# LPC18xx register map
File version: 18
Registers are 32-bit, read-write, reset 0x0 unless marked. A register's access mark holds for its fields unless they carry their own. Offsets are from the block's base; [hi:lo] are bit positions; {n}, {i} and the like mark numbered series.

## DAC — Product name title=UM10430 Chapter title=LPC18xx DAC Modification date=1/18/2011 Major revision=0 Minor revision=7
Base 0x400E1000
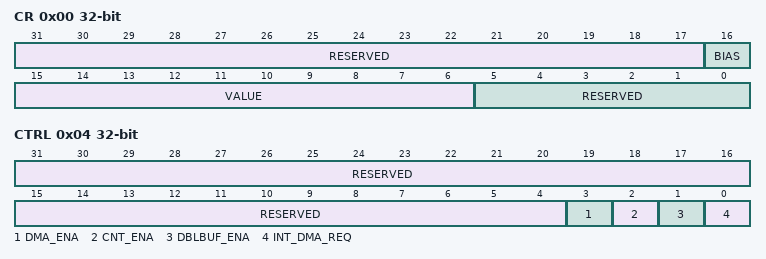
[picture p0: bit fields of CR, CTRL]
0x00 CR — DAC register. Holds the conversion data.
  [31:17] RESERVED — Reserved, user software should not write ones to reserved bits. The value read from a reserved bit is not defined.
  [16] BIAS — Settling time
    0=SHORT (The settling time of the DAC is 1 micros max, and the maximum current is 700 microA.); 1=LONG (The settling time of the DAC is 2.5 micros and the maximum current is 350 microA.)
  [15:6] VALUE — After the selected settling time after this field is written with a new VALUE, the voltage on the DACOUT pin (with respect to VSSA) is VALUE/1024 X VDDA.
  [5:0] RESERVED — Reserved, user software should not write ones to reserved bits. The value read from a reserved bit is not defined.
0x04 CTRL — DAC control register.
  [31:4] RESERVED — Reserved, user software should not write ones to reserved bits. The value read from a reserved bit is not defined.
  [3] DMA_ENA — DMA enable
    0=DISABLED (DMA access is disabled.); 1=ENABLED (DMA Burst Request Input 15 is enabled for the DAC (see Table 136).)
  [2] CNT_ENA — DMA time-out
    0=DISABLED (Time-out counter operation is disabled.); 1=ENABLED (Time-out counter operation is enabled.)
  [1] DBLBUF_ENA — DMA double-buffering
    0=DISABLED (DACR double-buffering is disabled.); 1=ENABLED (When this bit and the CNT_ENA bit are both set, the double-buffering feature in the DACR register will be enabled. Writes to the DACR register are written to a pre-buffer and then transferred to the DACR on the next time-out of the counter.)
  [0] INT_DMA_REQ — DMA request
    0=CLR (This bit is cleared on any write to the DACR register.); 1=SET (This bit is set by hardware when the timer times out.)
0x08 CNTVAL — DAC counter value register.
  [15:0] VALUE — 16-bit reload value for the DAC interrupt/DMA timer.

## GPIO_PORT
Base 0x400F4000
{0x0+i} B{i} (i=0..255) 8-bit — Byte pin registers port 0 to 5; pins PIOn_0 to PIOn_31
  [0] PBYTE — Read: state of the GPIOm[n] pin, regardless of direction, masking, or alternate function, except that pins configured as analog I/O always read as 0. Write: loads the pin's output bit.
{0x1000+4i} W{i} (i=0..255) — Word pin registers port 0 to 5
  [31:0] PWORD — Read 0: pin is LOW. Write 0: clear output bit. Read 0xFFFF FFFF: pin is HIGH. Write any value 0x0000 0001 to 0xFFFF FFFF: set output bit. Only 0 or 0xFFFF FFFF can be read. Writing any value other than 0 will set the output bit.
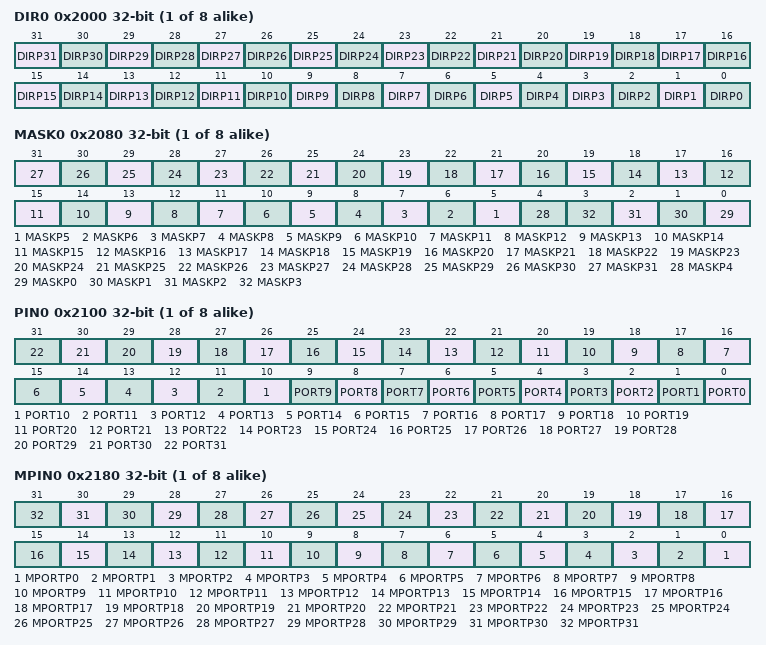
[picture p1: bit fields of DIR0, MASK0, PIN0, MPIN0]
{0x2000+4i} DIR{i} (i=0..7) — Direction registers port m
  [n] DIRP{n} (n=5..31) — Selects pin direction for pin GPIOm[n] (bit 0 = GPIOm[0], bit 1 = GPIOm[1], ..., bit 31 = GPIOm[31]). 0 = input. 1 = output.
  [n] DIRP{n} (n=0..4) — Selects pin direction for GPIOm[n] pin (bit 0 = GPIOm[0], bit 1 = GPIOm[1], ..., bit 31 = GPIOm[31]). 0 = input. 1 = output.
{0x2080+4i} MASK{i} (i=0..7) — Mask register port m
  [n] MASKP{n} (n=5..31) — Controls which bits corresponding to GPIOm[n] are active in the PIN register (bit 0 = GPIOm[0], bit 1 = GPIOm[1], ..., bit 31 = GPIOm[31]). 0 = Read MPORT: pin state; write MPORT: load output bit. 1 = Read MPORT: 0; write MPORT: output bit not affected.
  [4] MASKP4 — Controls which bits corresponding to GPIOm[n] are active in the P0/1PIN register (bit 0 = GPIOm[0], bit 1 = GPIOm[1], ..., bit 31 = GPIOm[31]). 0 = Read MPORT: pin state; write MPORT: load output bit. 1 = Read MPORT: 0; write MPORT: output bit not affected.
  [n] MASKP{n} (n=0..3) — Controls which bits corresponding to GPIOm[n] are active in the PIN register (bit 0 = GPIOm[0], bit 1 = GPIOm[1], ..., bit 31 = GPIOm[31]). 0 = Read MPORT: pin state; write MPORT: load output bit. 1 = Read MPORT: 0; write MPORT: output bit not affected.
{0x2100+4i} PIN{i} (i=0..7) — Port pin register port m
  [n] PORT{n} (n=0..31) — Reads pin states or loads output bits (bit 0 = GPIOm[0], bit 1 = GPIOm[1], ..., bit 31 = GPIOm[31]). 0 = Read: pin is low; write: clear output bit. 1 = Read: pin is high; write: set output bit.
{0x2180+4i} MPIN{i} (i=0..7) — Masked port register port m
  [n] MPORTP{n} (n=0..31) — Masked port register (bit 0 = GPIOm[0], bit 1 = GPIOm[1], ..., bit 31 = GPIOm[31]). 0 = Read: pin is LOW and/or the corresponding bit in the MASK register is 1; write: clear output bit if the corresponding bit in the MASK register is 0. 1 = Read: pin is HIGH and the corresponding bit in the MASK register is 0; write: set output bit if the corresponding bit in the MASK register is 0.
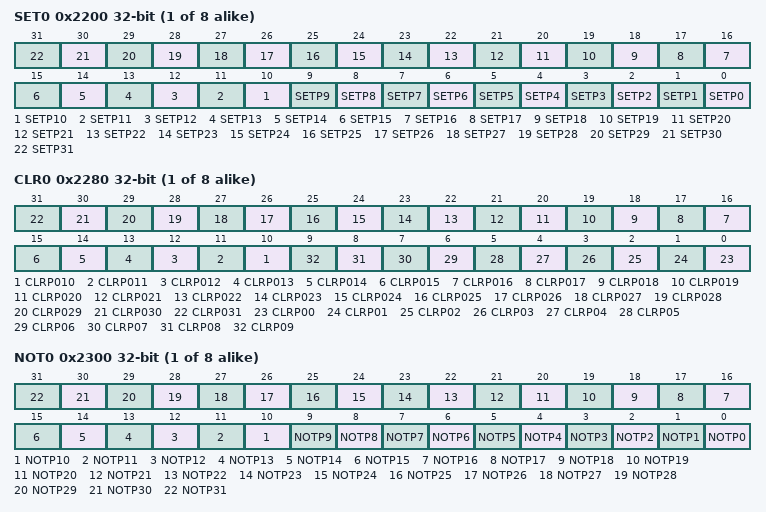
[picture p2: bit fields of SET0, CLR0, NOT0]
{0x2200+4i} SET{i} (i=0..7) — Write: Set register for port m Read: output bits for port m
  [n] SETP{n} (n=0..31) — Read or set output bits. 0 = Read: output bit: write: no operation. 1 = Read: output bit; write: set output bit.
{0x2280+4i} CLR{i} (i=0..7) wo reset not defined — Clear port m
  [n] CLRP{n:03} (n=10..31) — Clear output bits: 0 = No operation. 1 = Clear output bit.
  [n] CLRP{n:02} (n=0..9) — Clear output bits: 0 = No operation. 1 = Clear output bit.
{0x2300+4i} NOT{i} (i=0..7) wo reset not defined — Toggle port m
  [n] NOTP{n} (n=0..31) — Toggle output bits: 0 = no operation. 1 = Toggle output bit.
